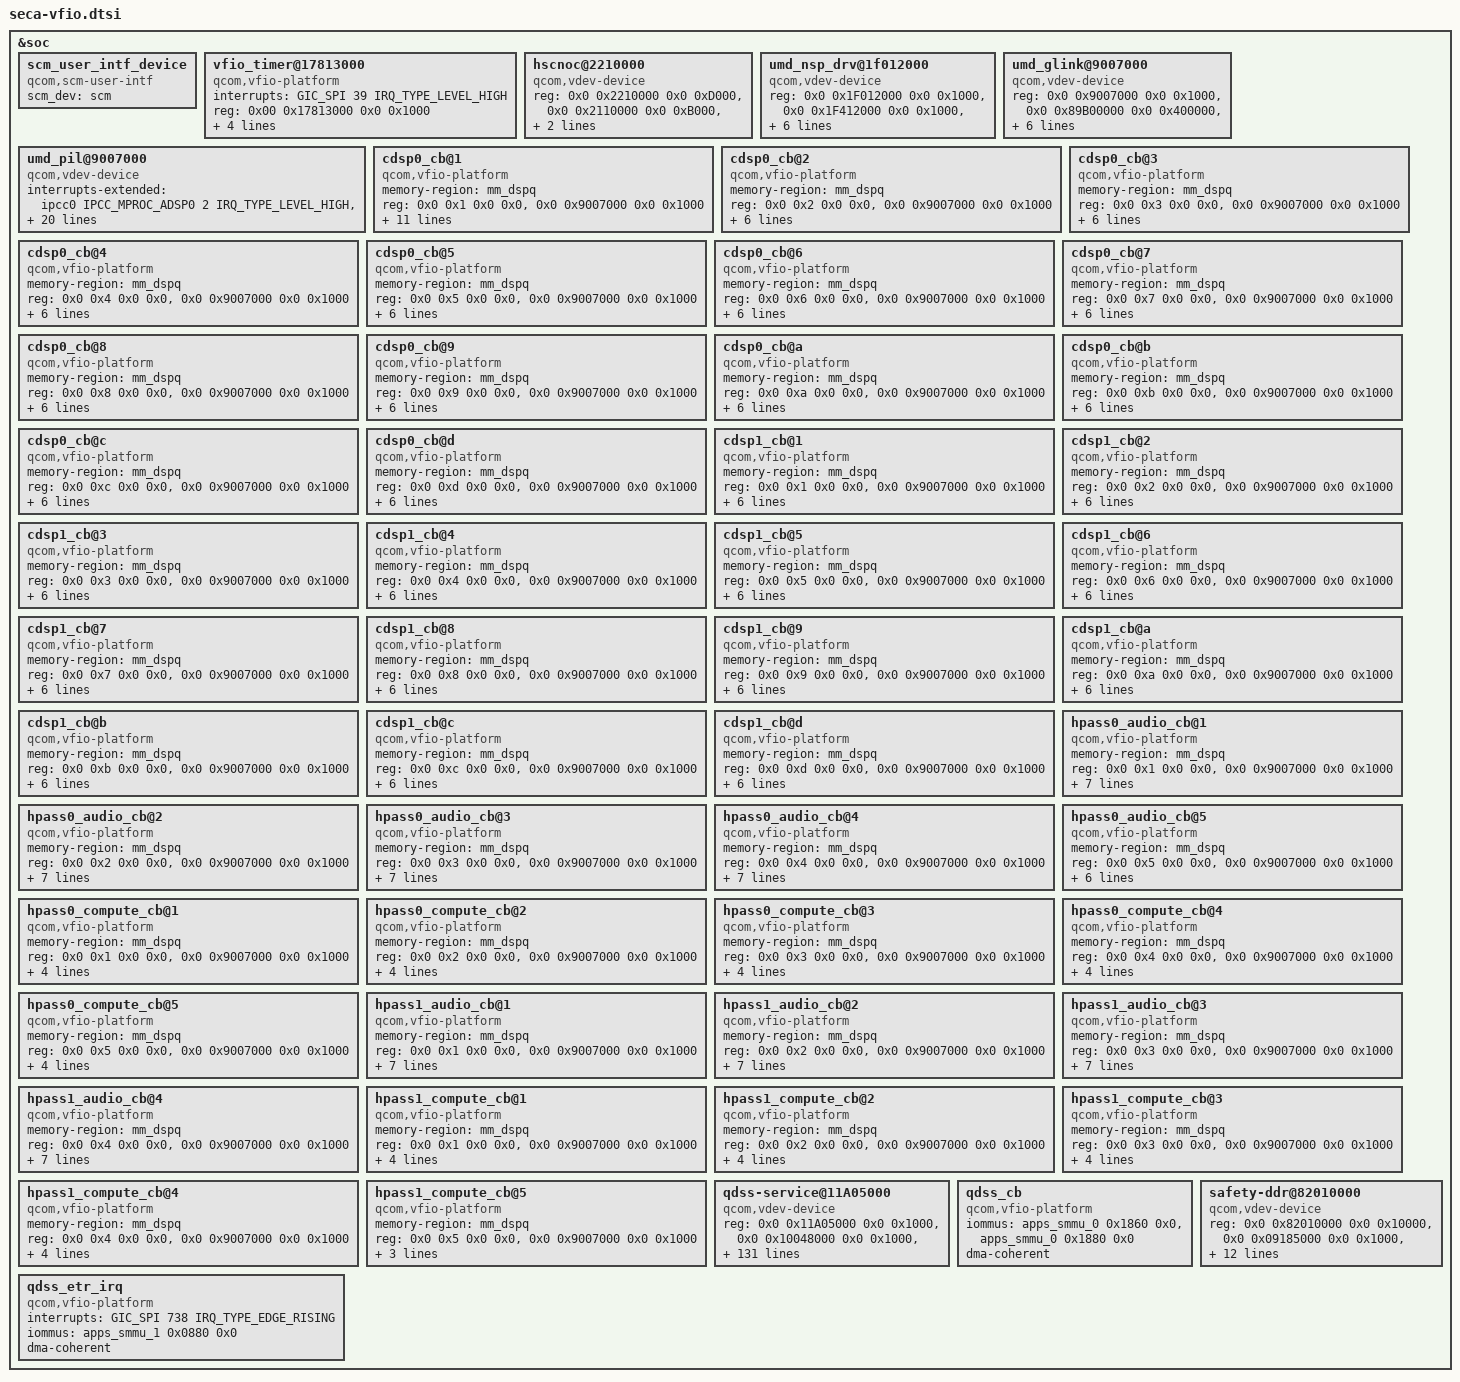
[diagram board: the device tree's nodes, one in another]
// SPDX-License-Identifier: BSD-3-Clause
/*
 * Copyright (c) Qualcomm Technologies, Inc. and/or its subsidiaries.
 */

&soc {
	scm_user_intf_device {
		compatible = "qcom,scm-user-intf";
		scm_dev = "scm";
		status = "ok";
	};

	vfio_timer@17813000 {
		compatible = "qcom,vfio-platform";
		interrupts = <GIC_SPI 39 IRQ_TYPE_LEVEL_HIGH>;
		reg = <0x00 0x17813000 0x0 0x1000>;
		iommus = <&apps_smmu_0 0x1980 0x0>;
		qcom,iommu-dma-addr-pool = <0x0 0x60002000 0x0 0x1FFFE000>;
		dma-coherent;
	};

	hscnoc@2210000 {
		compatible = "qcom,vdev-device";
		reg = <0x0 0x2210000 0x0 0xD000>,
		<0x0 0x2110000 0x0 0xB000>,
		<0x0 0x2A10000 0x0 0xD000>,
		<0x0 0x100D000 0x0 0x35000>;
	};

	/* NSP Driver mapping  */
	umd_nsp_drv@1f012000 {
		compatible = "qcom,vdev-device";
		reg = <0x0 0x1F012000 0x0 0x1000>,
		      <0x0 0x1F412000 0x0 0x1000>,
		      <0x0 0x05710000 0x0 0x1000>;

		interrupts = <GIC_SPI 946 IRQ_TYPE_LEVEL_HIGH>,
			     <GIC_SPI 499 IRQ_TYPE_LEVEL_HIGH>,
			     <GIC_SPI 945 IRQ_TYPE_LEVEL_HIGH>,
			     <GIC_SPI 500 IRQ_TYPE_LEVEL_HIGH>,
			     <GIC_SPI 160 IRQ_TYPE_LEVEL_HIGH>;
	};

	/* GLINK Context Banks - Updated for Seca */
	umd_glink@9007000 {
		compatible = "qcom,vdev-device";
		reg = <0x0 0x9007000 0x0 0x1000>,
		    <0x0 0x89B00000 0x0 0x400000>,
		    <0x0 0x01FD4000 0x0 0x1000>;
		interrupts-extended =
			<&ipcc0 IPCC_MPROC_ADSP0 0 IRQ_TYPE_LEVEL_HIGH>,
			<&ipcc0 IPCC_MPROC_ADSP1 0 IRQ_TYPE_LEVEL_HIGH>,
			<&ipcc0 IPCC_MPROC_NSP0 0 IRQ_TYPE_LEVEL_HIGH>,
			<&ipcc0 IPCC_MPROC_NSP1 0 IRQ_TYPE_LEVEL_HIGH>;
	};

	/* PIL Context Banks - Updated for Seca */
	umd_pil@9007000 {
		compatible = "qcom,vdev-device";
		interrupts-extended = <&ipcc0 IPCC_MPROC_ADSP0 2 IRQ_TYPE_LEVEL_HIGH>,
			<&ipcc0 IPCC_MPROC_ADSP1 2 IRQ_TYPE_LEVEL_HIGH>,
			<&ipcc0 IPCC_MPROC_NSP0 2 IRQ_TYPE_LEVEL_HIGH>,
			<&ipcc0 IPCC_MPROC_NSP1 2 IRQ_TYPE_LEVEL_HIGH>,
			<&ipcc0 IPCC_MPROC_AOP  0 IRQ_TYPE_LEVEL_HIGH>,
			<&intc GIC_SPI 159 IRQ_TYPE_EDGE_RISING>,
			<&intc GIC_SPI 155 IRQ_TYPE_EDGE_RISING>,
			<&intc GIC_SPI 178 IRQ_TYPE_EDGE_RISING>;

		memory-region = <&pil_umd_reserved
			&hpass_dsp0_mem
			&hpass_dsp0_dtb_mem
			&hpass_dsp1_mem
			&hpass_dsp1_dtb_mem
			&cdsp0_mem
			&q6_cdsp0_dtb_mem
			&cdsp1_mem
			&q6_cdsp1_dtb_mem
			&gpu_microcode_mem
			&gpu_microcode_2_mem
			&soccp_mem
			&video_mem
			&cvp_mem
			&camera_icp_1_mem
			&camera_icp_2_mem>;

		reg = <0x0 0x9007000 0x0 0x1000>,
		    <0x0 0x89B00000 0x0 0x400000>,
		    <0x0 0x01FD4000 0x0 0x1000>,
		    <0x0 0x8c900000 0x0 0x800000>,
		    <0x0 0x14680000 0x0 0x1000>,
		    <0x0 0xc300000 0x0 0x1000>;
	};

	cdsp0_cb@1 {
		compatible = "qcom,vfio-platform";
		memory-region = <&mm_dspq>;
		reg = <0x0 0x1 0x0 0x0>,
		    <0x0 0x9007000 0x0 0x1000>;
		interrupts-extended = <&ipcc0 IPCC_MPROC_ADSP0 3 IRQ_TYPE_LEVEL_HIGH>,
			<&ipcc0 IPCC_MPROC_NSP0 3 IRQ_TYPE_LEVEL_HIGH>,
			<&ipcc0 IPCC_MPROC_NSP1 3 IRQ_TYPE_LEVEL_HIGH>,
			<&ipcc0 IPCC_MPROC_ADSP1 3 IRQ_TYPE_LEVEL_HIGH>;
		iommus = <&apps_smmu_2 0x0301 0x0040>,
		       <&apps_smmu_2 0x0341 0x0040>,
		       <&apps_smmu_2 0x0361 0x0000>;
		qcom,iommu-dma-addr-range = <0x0 0x1000 0x2 0x0>;
		qcom,iova-align-shift-max = <21>;
		dma-coherent;
	};

	cdsp0_cb@2 {
		compatible = "qcom,vfio-platform";
		memory-region = <&mm_dspq>;
		reg = <0x0 0x2 0x0 0x0>,
		     <0x0 0x9007000 0x0 0x1000>;
		iommus = <&apps_smmu_2 0x0302 0x0040>,
		       <&apps_smmu_2 0x0342 0x0040>,
		       <&apps_smmu_2 0x0362 0x0000>;
		qcom,iommu-dma-addr-range = <0x0 0x1000 0x2 0x0>;
		qcom,iova-align-shift-max = <21>;
		dma-coherent;
	};

	cdsp0_cb@3 {
		compatible = "qcom,vfio-platform";
		memory-region = <&mm_dspq>;
		reg = <0x0 0x3 0x0 0x0>,
		     <0x0 0x9007000 0x0 0x1000>;
		iommus = <&apps_smmu_2 0x0303 0x0040>,
		       <&apps_smmu_2 0x0343 0x0040>,
		       <&apps_smmu_2 0x0363 0x0000>;
		qcom,iommu-dma-addr-range = <0x0 0x1000 0x2 0x0>;
		qcom,iova-align-shift-max = <21>;
		dma-coherent;
	};

	cdsp0_cb@4 {
		compatible = "qcom,vfio-platform";
		memory-region = <&mm_dspq>;
		reg = <0x0 0x4 0x0 0x0>,
		     <0x0 0x9007000 0x0 0x1000>;
		iommus = <&apps_smmu_2 0x0304 0x0040>,
		       <&apps_smmu_2 0x0344 0x0040>,
		       <&apps_smmu_2 0x0364 0x0000>;
		qcom,iommu-dma-addr-range = <0x0 0x1000 0x2 0x0>;
		qcom,iova-align-shift-max = <21>;
		dma-coherent;
	};

	cdsp0_cb@5 {
		compatible = "qcom,vfio-platform";
		memory-region = <&mm_dspq>;
		reg = <0x0 0x5 0x0 0x0>,
		     <0x0 0x9007000 0x0 0x1000>;
		iommus = <&apps_smmu_2 0x0305 0x0040>,
		       <&apps_smmu_2 0x0345 0x0040>,
		       <&apps_smmu_2 0x0365 0x0000>;
		qcom,iommu-dma-addr-range = <0x0 0x1000 0x2 0x0>;
		qcom,iova-align-shift-max = <21>;
		dma-coherent;
	};

	cdsp0_cb@6 {
		compatible = "qcom,vfio-platform";
		memory-region = <&mm_dspq>;
		reg = <0x0 0x6 0x0 0x0>,
		     <0x0 0x9007000 0x0 0x1000>;
		iommus = <&apps_smmu_2 0x0306 0x0040>,
		       <&apps_smmu_2 0x0346 0x0040>,
		       <&apps_smmu_2 0x0366 0x0000>;
		qcom,iommu-dma-addr-range = <0x0 0x1000 0x2 0x0>;
		qcom,iova-align-shift-max = <21>;
		dma-coherent;
	};

	cdsp0_cb@7 {
		compatible = "qcom,vfio-platform";
		memory-region = <&mm_dspq>;
		reg = <0x0 0x7 0x0 0x0>,
		     <0x0 0x9007000 0x0 0x1000>;
		iommus = <&apps_smmu_2 0x0307 0x0040>,
		       <&apps_smmu_2 0x0347 0x0040>,
		       <&apps_smmu_2 0x0367 0x0000>;
		qcom,iommu-dma-addr-range = <0x0 0x1000 0x2 0x0>;
		qcom,iova-align-shift-max = <21>;
		dma-coherent;
	};

	cdsp0_cb@8 {
		compatible = "qcom,vfio-platform";
		memory-region = <&mm_dspq>;
		reg = <0x0 0x8 0x0 0x0>,
		     <0x0 0x9007000 0x0 0x1000>;
		iommus = <&apps_smmu_2 0x0308 0x0040>,
		       <&apps_smmu_2 0x0348 0x0040>,
		       <&apps_smmu_2 0x0368 0x0000>;
		qcom,iommu-dma-addr-range = <0x0 0x1000 0x2 0x0>;
		qcom,iova-align-shift-max = <21>;
		dma-coherent;
	};

	cdsp0_cb@9 {
		compatible = "qcom,vfio-platform";
		memory-region = <&mm_dspq>;
		reg = <0x0 0x9 0x0 0x0>,
		     <0x0 0x9007000 0x0 0x1000>;
		iommus = <&apps_smmu_2 0x0309 0x0040>,
		       <&apps_smmu_2 0x0349 0x0040>,
		       <&apps_smmu_2 0x0369 0x0000>;
		qcom,iommu-dma-addr-range = <0x0 0x1000 0x2 0x0>;
		qcom,iova-align-shift-max = <21>;
		dma-coherent;
	};

	cdsp0_cb@a {
		compatible = "qcom,vfio-platform";
		memory-region = <&mm_dspq>;
		reg = <0x0 0xa 0x0 0x0>,
		     <0x0 0x9007000 0x0 0x1000>;
		iommus = <&apps_smmu_2 0x030a 0x0040>,
		       <&apps_smmu_2 0x034a 0x0040>,
		       <&apps_smmu_2 0x036a 0x0000>;
		qcom,iommu-dma-addr-range = <0x0 0x1000 0x2 0x0>;
		qcom,iova-align-shift-max = <21>;
		dma-coherent;
	};

	cdsp0_cb@b {
		compatible = "qcom,vfio-platform";
		memory-region = <&mm_dspq>;
		reg = <0x0 0xb 0x0 0x0>,
		     <0x0 0x9007000 0x0 0x1000>;
		iommus = <&apps_smmu_2 0x030b 0x0040>,
		       <&apps_smmu_2 0x034b 0x0040>,
		       <&apps_smmu_2 0x036b 0x0000>;
		qcom,iommu-dma-addr-range = <0x0 0x1000 0x2 0x0>;
		qcom,iova-align-shift-max = <21>;
		dma-coherent;
	};

	cdsp0_cb@c {
		compatible = "qcom,vfio-platform";
		memory-region = <&mm_dspq>;
		reg = <0x0 0xc 0x0 0x0>,
		     <0x0 0x9007000 0x0 0x1000>;
		iommus = <&apps_smmu_2 0x030c 0x0040>,
		       <&apps_smmu_2 0x034c 0x0040>,
		       <&apps_smmu_2 0x036c 0x0000>;
		qcom,iommu-dma-addr-range = <0x4 0x0 0x80 0x0>;
		qcom,iova-align-shift-max = <30>;
		dma-coherent;
	};

	cdsp0_cb@d {
		compatible = "qcom,vfio-platform";
		memory-region = <&mm_dspq>;
		reg = <0x0 0xd 0x0 0x0>,
		     <0x0 0x9007000 0x0 0x1000>;
		iommus = <&apps_smmu_2 0x030d 0x0040>,
		       <&apps_smmu_2 0x034d 0x0040>,
		       <&apps_smmu_2 0x036d 0x0000>;
		qcom,iommu-dma-addr-range = <0x4 0x0 0x80 0x0>;
		qcom,iova-align-shift-max = <30>;
		dma-coherent;
	};

	cdsp1_cb@1 {
		compatible = "qcom,vfio-platform";
		memory-region = <&mm_dspq>;
		reg = <0x0 0x1 0x0 0x0>,
		     <0x0 0x9007000 0x0 0x1000>;
		iommus = <&apps_smmu_2 0x0701 0x0040>,
		       <&apps_smmu_2 0x0741 0x0040>,
		       <&apps_smmu_2 0x0761 0x0000>;
		qcom,iommu-dma-addr-range = <0x0 0x1000 0x2 0x0>;
		qcom,iova-align-shift-max = <21>;
		dma-coherent;
	};

	cdsp1_cb@2 {
		compatible = "qcom,vfio-platform";
		memory-region = <&mm_dspq>;
		reg = <0x0 0x2 0x0 0x0>,
		     <0x0 0x9007000 0x0 0x1000>;
		iommus = <&apps_smmu_2 0x0702 0x0040>,
		       <&apps_smmu_2 0x0742 0x0040>,
		       <&apps_smmu_2 0x0762 0x0000>;
		qcom,iommu-dma-addr-range = <0x0 0x1000 0x2 0x0>;
		qcom,iova-align-shift-max = <21>;
		dma-coherent;
	};

	cdsp1_cb@3 {
		compatible = "qcom,vfio-platform";
		memory-region = <&mm_dspq>;
		reg = <0x0 0x3 0x0 0x0>,
		     <0x0 0x9007000 0x0 0x1000>;
		iommus = <&apps_smmu_2 0x0703 0x0040>,
		       <&apps_smmu_2 0x0743 0x0040>,
		       <&apps_smmu_2 0x0763 0x0000>;
		qcom,iommu-dma-addr-range = <0x0 0x1000 0x2 0x0>;
		qcom,iova-align-shift-max = <21>;
		dma-coherent;
	};

	cdsp1_cb@4 {
		compatible = "qcom,vfio-platform";
		memory-region = <&mm_dspq>;
		reg = <0x0 0x4 0x0 0x0>,
		     <0x0 0x9007000 0x0 0x1000>;
		iommus = <&apps_smmu_2 0x0704 0x0040>,
		       <&apps_smmu_2 0x0744 0x0040>,
		       <&apps_smmu_2 0x0764 0x0000>;
		qcom,iommu-dma-addr-range = <0x0 0x1000 0x2 0x0>;
		qcom,iova-align-shift-max = <21>;
		dma-coherent;
	};

	cdsp1_cb@5 {
		compatible = "qcom,vfio-platform";
		memory-region = <&mm_dspq>;
		reg = <0x0 0x5 0x0 0x0>,
		     <0x0 0x9007000 0x0 0x1000>;
		iommus = <&apps_smmu_2 0x0705 0x0040>,
		       <&apps_smmu_2 0x0745 0x0040>,
		       <&apps_smmu_2 0x0765 0x0000>;
		qcom,iommu-dma-addr-range = <0x0 0x1000 0x2 0x0>;
		qcom,iova-align-shift-max = <21>;
		dma-coherent;
	};

	cdsp1_cb@6 {
		compatible = "qcom,vfio-platform";
		memory-region = <&mm_dspq>;
		reg = <0x0 0x6 0x0 0x0>,
		     <0x0 0x9007000 0x0 0x1000>;
		iommus = <&apps_smmu_2 0x0706 0x0040>,
		       <&apps_smmu_2 0x0746 0x0040>,
		       <&apps_smmu_2 0x0766 0x0000>;
		qcom,iommu-dma-addr-range = <0x0 0x1000 0x2 0x0>;
		qcom,iova-align-shift-max = <21>;
		dma-coherent;
	};

	cdsp1_cb@7 {
		compatible = "qcom,vfio-platform";
		memory-region = <&mm_dspq>;
		reg = <0x0 0x7 0x0 0x0>,
		     <0x0 0x9007000 0x0 0x1000>;
		iommus = <&apps_smmu_2 0x0707 0x0040>,
		       <&apps_smmu_2 0x0747 0x0040>,
		       <&apps_smmu_2 0x0767 0x0000>;
		qcom,iommu-dma-addr-range = <0x0 0x1000 0x2 0x0>;
		qcom,iova-align-shift-max = <21>;
		dma-coherent;
	};

	cdsp1_cb@8 {
		compatible = "qcom,vfio-platform";
		memory-region = <&mm_dspq>;
		reg = <0x0 0x8 0x0 0x0>,
		     <0x0 0x9007000 0x0 0x1000>;
		iommus = <&apps_smmu_2 0x0708 0x0040>,
		       <&apps_smmu_2 0x0748 0x0040>,
		       <&apps_smmu_2 0x0768 0x0000>;
                qcom,iommu-dma-addr-range = <0x0 0x1000 0x2 0x0>;
		qcom,iova-align-shift-max = <21>;
		dma-coherent;
	};

	cdsp1_cb@9 {
		compatible = "qcom,vfio-platform";
		memory-region = <&mm_dspq>;
		reg = <0x0 0x9 0x0 0x0>,
		     <0x0 0x9007000 0x0 0x1000>;
		iommus = <&apps_smmu_2 0x0709 0x0040>,
		       <&apps_smmu_2 0x0749 0x0040>,
		       <&apps_smmu_2 0x0769 0x0000>;
		qcom,iommu-dma-addr-range = <0x0 0x1000 0x2 0x0>;
		qcom,iova-align-shift-max = <21>;
		dma-coherent;
	};

	cdsp1_cb@a {
		compatible = "qcom,vfio-platform";
		memory-region = <&mm_dspq>;
		reg = <0x0 0xa 0x0 0x0>,
		     <0x0 0x9007000 0x0 0x1000>;
		iommus = <&apps_smmu_2 0x070a 0x0040>,
		       <&apps_smmu_2 0x074a 0x0040>,
		       <&apps_smmu_2 0x076a 0x0000>;
		qcom,iommu-dma-addr-range = <0x0 0x1000 0x2 0x0>;
		qcom,iova-align-shift-max = <21>;
		dma-coherent;
	};

	cdsp1_cb@b {
		compatible = "qcom,vfio-platform";
		memory-region = <&mm_dspq>;
		reg = <0x0 0xb 0x0 0x0>,
		     <0x0 0x9007000 0x0 0x1000>;
		iommus = <&apps_smmu_2 0x070b 0x0040>,
		       <&apps_smmu_2 0x074b 0x0040>,
		       <&apps_smmu_2 0x076b 0x0000>;
		qcom,iommu-dma-addr-range = <0x0 0x1000 0x2 0x0>;
		qcom,iova-align-shift-max = <21>;
		dma-coherent;
	};

	cdsp1_cb@c {
		compatible = "qcom,vfio-platform";
		memory-region = <&mm_dspq>;
		reg = <0x0 0xc 0x0 0x0>,
		     <0x0 0x9007000 0x0 0x1000>;
		iommus = <&apps_smmu_2 0x070c 0x0040>,
		       <&apps_smmu_2 0x074c 0x0040>,
		       <&apps_smmu_2 0x076c 0x0000>;
		qcom,iommu-dma-addr-range = <0x4 0x0 0x80 0x0>;
		qcom,iova-align-shift-max = <30>;
		dma-coherent;
	};

	cdsp1_cb@d {
		compatible = "qcom,vfio-platform";
		memory-region = <&mm_dspq>;
		reg = <0x0 0xd 0x0 0x0>,
		     <0x0 0x9007000 0x0 0x1000>;
		iommus = <&apps_smmu_2 0x070d 0x0040>,
		       <&apps_smmu_2 0x074d 0x0040>,
		       <&apps_smmu_2 0x076d 0x0000>;
		qcom,iommu-dma-addr-range = <0x4 0x0 0x80 0x0>;
		qcom,iova-align-shift-max = <30>;
		dma-coherent;
	};

	hpass0_audio_cb@1 {
		compatible = "qcom,vfio-platform";
		memory-region = <&mm_dspq>;
		reg = <0x0 0x1 0x0 0x0>,
			<0x0 0x9007000 0x0 0x1000>;
		iommus = <&apps_smmu_2 0x09E3 0x0000>,
		       <&apps_smmu_2 0x0A43 0x0020>,
		       <&apps_smmu_2 0x0A63 0x0020>,
		       <&apps_smmu_2 0x0A83 0x0000>;
		qcom,iommu-dma-addr-range = <0x0 0x1000 0x2 0x0>;
		qcom,iova-align-shift-max = <21>;
		dma-coherent;
	};

	hpass0_audio_cb@2 {
		compatible = "qcom,vfio-platform";
		memory-region = <&mm_dspq>;
		reg = <0x0 0x2 0x0 0x0>,
			<0x0 0x9007000 0x0 0x1000>;
		iommus = <&apps_smmu_2 0x09E4 0x0000>,
		       <&apps_smmu_2 0x0A44 0x0020>,
		       <&apps_smmu_2 0x0A64 0x0020>,
		       <&apps_smmu_2 0x0A84 0x0000>;
		qcom,iommu-dma-addr-range = <0x0 0x1000 0x2 0x0>;
		qcom,iova-align-shift-max = <21>;
		dma-coherent;
	};

	hpass0_audio_cb@3 {
		compatible = "qcom,vfio-platform";
		memory-region = <&mm_dspq>;
		reg = <0x0 0x3 0x0 0x0>,
			<0x0 0x9007000 0x0 0x1000>;
		iommus = <&apps_smmu_2 0x09E5 0x0000>,
		       <&apps_smmu_2 0x0A45 0x0020>,
		       <&apps_smmu_2 0x0A65 0x0020>,
		       <&apps_smmu_2 0x0A85 0x0000>;
		qcom,iommu-dma-addr-range = <0x0 0x1000 0x2 0x0>;
		qcom,iova-align-shift-max = <21>;
		dma-coherent;
	};

	hpass0_audio_cb@4 {
		compatible = "qcom,vfio-platform";
		memory-region = <&mm_dspq>;
		reg = <0x0 0x4 0x0 0x0>,
			<0x0 0x9007000 0x0 0x1000>;
		iommus = <&apps_smmu_2 0x09E6 0x0000>,
		       <&apps_smmu_2 0x0A46 0x0020>,
		       <&apps_smmu_2 0x0A66 0x0020>,
		       <&apps_smmu_2 0x0A86 0x0000>;
		qcom,iommu-dma-addr-range = <0x0 0x1000 0x2 0x0>;
		qcom,iova-align-shift-max = <21>;
		dma-coherent;
	};

	hpass0_audio_cb@5 {
		compatible = "qcom,vfio-platform";
		memory-region = <&mm_dspq>;
		reg = <0x0 0x5 0x0 0x0>,
			<0x0 0x9007000 0x0 0x1000>;
		iommus = <&apps_smmu_2 0x0A47 0x0020>,
		       <&apps_smmu_2 0x0A67 0x0020>,
		       <&apps_smmu_2 0x0A87 0x0000>;
		qcom,iommu-dma-addr-range = <0x0 0x1000 0x2 0x0>;
		qcom,iova-align-shift-max = <21>;
		dma-coherent;
	};

	hpass0_compute_cb@1 {
		compatible = "qcom,vfio-platform";
		memory-region = <&mm_dspq>;
		reg = <0x0 0x1 0x0 0x0>,
			<0x0 0x9007000 0x0 0x1000>;
		iommus = <&apps_smmu_2 0x0DE3 0x0000>;
		qcom,iommu-dma-addr-range = <0x0 0x1000 0x2 0x0>;
		qcom,iova-align-shift-max = <21>;
		dma-coherent;
	};

	hpass0_compute_cb@2 {
		compatible = "qcom,vfio-platform";
		memory-region = <&mm_dspq>;
		reg = <0x0 0x2 0x0 0x0>,
			<0x0 0x9007000 0x0 0x1000>;
		iommus = <&apps_smmu_2 0x0DE4 0x0000>;
		qcom,iommu-dma-addr-range = <0x0 0x1000 0x2 0x0>;
		qcom,iova-align-shift-max = <21>;
		dma-coherent;
	};

	hpass0_compute_cb@3 {
		compatible = "qcom,vfio-platform";
		memory-region = <&mm_dspq>;
		reg = <0x0 0x3 0x0 0x0>,
			<0x0 0x9007000 0x0 0x1000>;
		iommus = <&apps_smmu_2 0x0DE5 0x0000>;
		qcom,iommu-dma-addr-range = <0x0 0x1000 0x2 0x0>;
		qcom,iova-align-shift-max = <21>;
		dma-coherent;
	};

	hpass0_compute_cb@4 {
		compatible = "qcom,vfio-platform";
		memory-region = <&mm_dspq>;
		reg = <0x0 0x4 0x0 0x0>,
			<0x0 0x9007000 0x0 0x1000>;
		iommus = <&apps_smmu_2 0x0DE6 0x0000>;
		qcom,iommu-dma-addr-range = <0x4 0x0 0x80 0x0>;
		qcom,iova-align-shift-max = <30>;
		dma-coherent;
	};

	hpass0_compute_cb@5 {
		compatible = "qcom,vfio-platform";
		memory-region = <&mm_dspq>;
		reg = <0x0 0x5 0x0 0x0>,
			<0x0 0x9007000 0x0 0x1000>;
		iommus = <&apps_smmu_2 0x0DE7 0x0000>;
		qcom,iommu-dma-addr-range = <0x4 0x0 0x80 0x0>;
		qcom,iova-align-shift-max = <30>;
		dma-coherent;
	};

	/* HPASS1 Audio Context Banks - Updated for Seca */
	hpass1_audio_cb@1 {
		compatible = "qcom,vfio-platform";
		memory-region = <&mm_dspq>;
		reg = <0x0 0x1 0x0 0x0>,
			<0x0 0x9007000 0x0 0x1000>;
		iommus = <&apps_smmu_2 0x0A0B 0x0080>,
		       <&apps_smmu_2 0x0A4B 0x0020>,
		       <&apps_smmu_2 0x0A6B 0x0020>,
		       <&apps_smmu_2 0x0A8B 0x0080>;
		qcom,iommu-dma-addr-range = <0x0 0x1000 0x2 0x0>;
		qcom,iova-align-shift-max = <21>;
		dma-coherent;
	};

	hpass1_audio_cb@2 {
		compatible = "qcom,vfio-platform";
		memory-region = <&mm_dspq>;
		reg = <0x0 0x2 0x0 0x0>,
			<0x0 0x9007000 0x0 0x1000>;
		iommus = <&apps_smmu_2 0x0A0C 0x0080>,
		       <&apps_smmu_2 0x0A4C 0x0020>,
		       <&apps_smmu_2 0x0A6C 0x0020>,
		       <&apps_smmu_2 0x0A8C 0x0080>;
		qcom,iommu-dma-addr-range = <0x0 0x1000 0x2 0x0>;
		qcom,iova-align-shift-max = <21>;
		dma-coherent;
	};

	hpass1_audio_cb@3 {
		compatible = "qcom,vfio-platform";
		memory-region = <&mm_dspq>;
		reg = <0x0 0x3 0x0 0x0>,
			<0x0 0x9007000 0x0 0x1000>;
		iommus = <&apps_smmu_2 0x0A0D 0x0080>,
		       <&apps_smmu_2 0x0A4D 0x0020>,
		       <&apps_smmu_2 0x0A6D 0x0020>,
		       <&apps_smmu_2 0x0A8D 0x0080>;
		qcom,iommu-dma-addr-range = <0x0 0x1000 0x2 0x0>;
		qcom,iova-align-shift-max = <21>;
		dma-coherent;
	};

	hpass1_audio_cb@4 {
		compatible = "qcom,vfio-platform";
		memory-region = <&mm_dspq>;
		reg = <0x0 0x4 0x0 0x0>,
			<0x0 0x9007000 0x0 0x1000>;
		iommus = <&apps_smmu_2 0x0A0E 0x0080>,
		       <&apps_smmu_2 0x0A4E 0x0020>,
		       <&apps_smmu_2 0x0A6E 0x0020>,
		       <&apps_smmu_2 0x0A8E 0x0080>;
		qcom,iommu-dma-addr-range = <0x0 0x1000 0x2 0x0>;
		qcom,iova-align-shift-max = <21>;
		dma-coherent;
	};

	hpass1_compute_cb@1 {
		compatible = "qcom,vfio-platform";
		memory-region = <&mm_dspq>;
		reg = <0x0 0x1 0x0 0x0>,
			<0x0 0x9007000 0x0 0x1000>;
		iommus = <&apps_smmu_2 0x0E0B 0x0000>;
		qcom,iommu-dma-addr-range = <0x0 0x1000 0x2 0x0>;
		qcom,iova-align-shift-max = <21>;
		dma-coherent;
	};

	hpass1_compute_cb@2 {
		compatible = "qcom,vfio-platform";
		memory-region = <&mm_dspq>;
		reg = <0x0 0x2 0x0 0x0>,
			<0x0 0x9007000 0x0 0x1000>;
		iommus = <&apps_smmu_2 0x0E0C 0x0000>;
		qcom,iommu-dma-addr-range = <0x0 0x1000 0x2 0x0>;
		qcom,iova-align-shift-max = <21>;
		dma-coherent;
	};

	hpass1_compute_cb@3 {
		compatible = "qcom,vfio-platform";
		memory-region = <&mm_dspq>;
		reg = <0x0 0x3 0x0 0x0>,
			<0x0 0x9007000 0x0 0x1000>;
		iommus = <&apps_smmu_2 0x0E0D 0x0000>;
		qcom,iommu-dma-addr-range = <0x0 0x1000 0x2 0x0>;
		qcom,iova-align-shift-max = <21>;
		dma-coherent;
	};

	hpass1_compute_cb@4 {
		compatible = "qcom,vfio-platform";
		memory-region = <&mm_dspq>;
		reg = <0x0 0x4 0x0 0x0>,
			<0x0 0x9007000 0x0 0x1000>;
		iommus = <&apps_smmu_2 0x0E0E 0x0000>;
		qcom,iommu-dma-addr-range = <0x4 0x0 0x80 0x0>;
		qcom,iova-align-shift-max = <30>;
		dma-coherent;
	};

	hpass1_compute_cb@5 {
		compatible = "qcom,vfio-platform";
		memory-region = <&mm_dspq>;
		reg = <0x0 0x5 0x0 0x0>,
			<0x0 0x9007000 0x0 0x1000>;
		iommus = <&apps_smmu_2 0x0E0F 0x0000>;
		qcom,iommu-dma-addr-range = <0x4 0x0 0x80 0x0>;
		qcom,iova-align-shift-max = <30>;
	};

	qdss-service@11A05000 {
		compatible = "qcom,vdev-device";
		reg = <0x0 0x11A05000 0x0 0x1000>,          //tmc_etf
			<0x0 0x10048000 0x0 0x1000>,        //tmc_etr
			<0x0 0x11A06000 0x0 0x1000>,        //swao_replicator
			<0x0 0x11A07000 0x0 0x1000>,        //swao_replicator_1
			<0x0 0x10046000 0x0 0x1000>,        //qdss_replicator
			<0x0 0x1004E000 0x0 0x1000>,        //etr_replicator
			<0x0 0x10001000 0x0 0x1000>,        //csr
			<0x0 0x11A11000 0x0 0x1000>,        //swao_csr
			<0x0 0x10002000 0x0 0x1000>,        //stm
			<0x0 0x12D21000 0x0 0x1000>,        //etm-nsp0
			<0x0 0x12D21000 0x0 0x1000>,        //etm-nsp1
			<0x0 0x12D21000 0x0 0x1000>,        //etm-nsp2
			<0x0 0x12D21000 0x0 0x1000>,        //etm-nsp3
			<0x0 0x12D21000 0x0 0x1000>,        //tpdm-apps
			<0x0 0x10041000 0x0 0x1000>,        //funnel_in0
			<0x0 0x11A04000 0x0 0x1000>,        //funnel_swao0
			<0x0 0x16000000 0x0 0x1000000>,     //STM 16MB
			<0x0 0x11A0E000 0x0 0x1000>,        //TGU
			<0x0 0x115BC000 0x0 0x1000>,        //QDSS_TNOC
			<0x0 0x117C9000 0x0 0x1000>,        //FUN_NSP_SS_0
			<0x0 0x117E9000 0x0 0x1000>,        //FUN_NSP_SS_1
			<0x0 0x118C9000 0x0 0x1000>,        //FUN_NSP_SS_2
			<0x0 0x118E9000 0x0 0x1000>,        //FUN_NSP_SS_3
			<0x0 0x11980000 0x0 0x1000>,        //HPASS_TNOC
			<0x0 0x119A0000 0x0 0x1000>,         //HPASS_DSB_TPDM
			<0x0 0x117C4000 0x0 0x1000>,         //NSP0_DSB_TPDM
			<0x0 0x117E4000 0x0 0x1000>,         //NSP1_DSB_TPDM
			<0x0 0x118C4000 0x0 0x1000>,         //NSP2_DSB_TPDM
			<0x0 0x118E4000 0x0 0x1000>,         //NSP3_DSB_TPDM
			<0x0 0x119A8000 0x0 0x1000>,         //HPASS_DL_TPDA
			<0x0 0x117C8000 0x0 0x1000>,         //NSP0_TPDA
			<0x0 0x117E8000 0x0 0x1000>,         //NSP1_TPDA
			<0x0 0x118C8000 0x0 0x1000>,         //NSP2_TPDA
			<0x0 0x118E8000 0x0 0x1000>,         //NSP3_TPDA
			<0x0 0x117C2000 0x0 0x1000>,         //NSP0_CMSR1
			<0x0 0x117C3000 0x0 0x1000>,         //NSP0_CMSR2
			<0x0 0x1318B000 0x0 0x1000>,         //APPS_TPDA
			<0x0 0x13188000 0x0 0x1000>,         //APPS_DSB0_TPDM
			<0x0 0x13189000 0x0 0x1000>,         //APPS_DSP1_TPDM
			<0x0 0x13080000 0x0 0x1000>,         //APPS_FUN
			<0x0 0x11A08000 0x0 0x1000>,         //SWAO_TPDA
			<0x0 0x11A09000 0x0 0x1000>,         //SWAO0_TPDM
			<0x0 0x11A0A000 0x0 0x1000>,         //SWAO1_TPDM
			<0x0 0x11A0B000 0x0 0x1000>,         //SWAO2_TPDM
			<0x0 0x11A0C000 0x0 0x1000>,         //SWAO3_TPDM
			<0x0 0x11A03000 0x0 0x1000>,         //SWAO4_TPDM
			<0x0 0x11A0D000 0x0 0x1000>,         //SWAO_DSB_TPDM
			<0x0 0x117C0000 0x0 0x1000>,         //NSP0_TURING_LLM
			<0x0 0x117C1000 0x0 0x1000>,         //NSP0_TURING_LLM2
			<0x0 0x117C5000 0x0 0x1000>,         //NSP0_DPM1
			<0x0 0x117C6000 0x0 0x1000>,         //NSP0_DPM2
			<0x0 0x117E0000 0x0 0x1000>,         //NSP1_TURING_LLM
			<0x0 0x117E1000 0x0 0x1000>,         //NSP1_TURING_LLM2
			<0x0 0x117E5000 0x0 0x1000>,         //NSP1_DPM1
			<0x0 0x117E6000 0x0 0x1000>,         //NSP1_DPM2
			<0x0 0x118C0000 0x0 0x1000>,         //NSP2_TURING_LLM
			<0x0 0x118C1000 0x0 0x1000>,         //NSP2_TURING_LLM2
			<0x0 0x118C5000 0x0 0x1000>,         //NSP2_DPM1
			<0x0 0x118C6000 0x0 0x1000>,         //NSP2_DPM2
			<0x0 0x118E0000 0x0 0x1000>,         //NSP3_TURING_LLM
			<0x0 0x118E1000 0x0 0x1000>,         //NSP3_TURING_LLM2
			<0x0 0x118E5000 0x0 0x1000>,         //NSP3_DPM1
			<0x0 0x118E6000 0x0 0x1000>,         //NSP3_DPM2
			<0x0 0x117E2000 0x0 0x1000>,         //NSP1_CMSR1
			<0x0 0x117E3000 0x0 0x1000>,         //NSP1_CMSR2
			<0x0 0x118C2000 0x0 0x1000>,         //NSP2_CMSR1
			<0x0 0x118C3000 0x0 0x1000>,         //NSP2_CMSR2
			<0x0 0x118E2000 0x0 0x1000>,         //NSP3_CMSR1
			<0x0 0x118E3000 0x0 0x1000>,         //NSP3_CMSR2
			<0x0 0x119A1000 0x0 0x1000>,         //HPASS_CMB
			<0x0 0x119A2000 0x0 0x1000>,         //HPASS_LLM
			<0x0 0x119A3000 0x0 0x1000>,         //HPASS_LLM1
			<0x0 0x119A4000 0x0 0x1000>,         //HPASS_LLM2
			<0x0 0x119A5000 0x0 0x1000>,         //HPASS_DPM
			<0x0 0x119A6000 0x0 0x1000>,         //HPASS_DPM1
			<0x0 0x119A7000 0x0 0x1000>,         //HPASS_DPM2
			<0x0 0x119B0000 0x0 0x1000>,         //HPASS_RSCC
			<0x0 0x119B1000 0x0 0x1000>,         //HPASS_CESTA_DL_TPDA
			<0x0 0x19021000 0x0 0x1000>,         //NCC0_CORE0_ETM
			<0x0 0x19121000 0x0 0x1000>,         //NCC0_CORE1_ETM
			<0x0 0x19221000 0x0 0x1000>,         //NCC0_CORE2_ETM
			<0x0 0x19321000 0x0 0x1000>,         //NCC0_CORE3_ETM
			<0x0 0x19421000 0x0 0x1000>,         //NCC0_CORE4_ETM
			<0x0 0x19521000 0x0 0x1000>,         //NCC0_CORE5_ETM
			<0x0 0x1A021000 0x0 0x1000>,         //NCC1_CORE0_ETM
			<0x0 0x1A121000 0x0 0x1000>,         //NCC1_CORE1_ETM
			<0x0 0x1A221000 0x0 0x1000>,         //NCC1_CORE2_ETM
			<0x0 0x1A321000 0x0 0x1000>,         //NCC1_CORE3_ETM
			<0x0 0x1A421000 0x0 0x1000>,         //NCC1_CORE4_ETM
			<0x0 0x1A521000 0x0 0x1000>,         //NCC1_CORE5_ETM
			<0x0 0x1B021000 0x0 0x1000>,         //NCC2_CORE0_ETM
			<0x0 0x1B121000 0x0 0x1000>,         //NCC2_CORE1_ETM
			<0x0 0x1B221000 0x0 0x1000>,         //NCC2_CORE2_ETM
			<0x0 0x1B321000 0x0 0x1000>,         //NCC2_CORE3_ETM
			<0x0 0x1B421000 0x0 0x1000>,         //NCC2_CORE4_ETM
			<0x0 0x1B521000 0x0 0x1000>,         //NCC2_CORE5_ETM
			<0x0 0x84000000 0x0 0x3000>,         //NCC_UETM_SHARED_MEM
			<0x0 0x1D081000 0x0 0x1000>,         //NCC0_FUN_1_1
			<0x0 0x1D014000 0x0 0x1000>,         //NCC0_FUN_1_2
			<0x0 0x1D001000 0x0 0x1000>,         //NCC0_FUN_2
			<0x0 0x1D009000 0x0 0x1000>,         //NCC0_ETF
			<0x0 0x1D181000 0x0 0x1000>,         //NCC1_FUN_1_1
			<0x0 0x1D114000 0x0 0x1000>,         //NCC1_FUN_1_2
			<0x0 0x1D101000 0x0 0x1000>,         //NCC1_FUN_2
			<0x0 0x1D109000 0x0 0x1000>,         //NCC1_ETF
			<0x0 0x1D281000 0x0 0x1000>,         //NCC2_FUN_1_1
			<0x0 0x1D214000 0x0 0x1000>,         //NCC2_FUN_1_2
			<0x0 0x1D201000 0x0 0x1000>,         //NCC2_FUN_2
			<0x0 0x1D209000 0x0 0x1000>,         //NCC2_ETF
			<0x0 0x1D090000 0x0 0x1000>,         //NCC0_CORE0_REP
			<0x0 0x1D0A0000 0x0 0x1000>,         //NCC0_CORE1_REP
			<0x0 0x1D0B0000 0x0 0x1000>,         //NCC0_CORE2_REP
			<0x0 0x1D0C0000 0x0 0x1000>,         //NCC0_CORE3_REP
			<0x0 0x1D0D0000 0x0 0x1000>,         //NCC0_CORE4_REP
			<0x0 0x1D0E0000 0x0 0x1000>,         //NCC0_CORE5_REP
			<0x0 0x1D190000 0x0 0x1000>,         //NCC1_CORE0_REP
			<0x0 0x1D1A0000 0x0 0x1000>,         //NCC1_CORE1_REP
			<0x0 0x1D1B0000 0x0 0x1000>,         //NCC1_CORE2_REP
			<0x0 0x1D1C0000 0x0 0x1000>,         //NCC1_CORE3_REP
			<0x0 0x1D1D0000 0x0 0x1000>,         //NCC1_CORE4_REP
			<0x0 0x1D1E0000 0x0 0x1000>,         //NCC1_CORE5_REP
			<0x0 0x1D290000 0x0 0x1000>,         //NCC2_CORE0_REP
			<0x0 0x1D2A0000 0x0 0x1000>,         //NCC2_CORE1_REP
			<0x0 0x1D2B0000 0x0 0x1000>,         //NCC2_CORE2_REP
			<0x0 0x1D2C0000 0x0 0x1000>,         //NCC2_CORE3_REP
			<0x0 0x1D2D0000 0x0 0x1000>,         //NCC2_CORE4_REP
			<0x0 0x1D2E0000 0x0 0x1000>,         //NCC2_CORE5_REP
			<0x0 0x1D008000 0x0 0x1000>,         //NCC0_UNCORE_ETF
			<0x0 0x1D108000 0x0 0x1000>,         //NCC1_UNCORE_ETF
			<0x0 0x1D208000 0x0 0x1000>,         //NCC2_UNCORE_ETF
			<0x0 0x1D00A000 0x0 0x1000>,         //NCC0_UNCORE_REP
			<0x0 0x1D10A000 0x0 0x1000>,         //NCC1_UNCORE_REP
			<0x0 0x1D20A000 0x0 0x1000>;         //NCC2_UNCORE_REP
	};

	qdss_cb {
		compatible = "qcom,vfio-platform";
		iommus = <&apps_smmu_0 0x1860 0x0>,
			<&apps_smmu_0 0x1880 0x0>;
		dma-coherent;
	};

	qdss_etr_irq {
		compatible = "qcom,vfio-platform";
		interrupts = <GIC_SPI 738 IRQ_TYPE_EDGE_RISING>;
		iommus = <&apps_smmu_1 0x0880 0x0>;
		dma-coherent;
	};

	safety-ddr@82010000 {
		compatible = "qcom,vdev-device";
		reg = <0x0 0x82010000 0x0 0x10000>,
			  <0x0 0x09185000 0x0 0x1000>,
			  <0x0 0x87200000 0x0 0x1000>,
			  <0x0 0x87ADB000 0x0 0x1000>,
			  <0x0 0x01F76000 0x0 0x3000>,
			  <0x0 0x1F73000  0x0 0x1000>,
			  <0x0 0x210AF000 0x0 0x4000000>,
			  <0x0 0x17F60000 0x0 0x2000>,
			  <0x0 0x19AA0000 0x0 0x2000>,
			  <0x0 0x87ADA000 0x0 0x2000>,
			  <0x0 0x01F97000 0x0 0x1000>,
			  <0x0 0x87AE3000 0x0 0x2000>;
		interrupts-extended = <&ipcc2 IPCC_COMPUTE_L1_SAIL0 1 IRQ_TYPE_LEVEL_HIGH>;
	};

};
